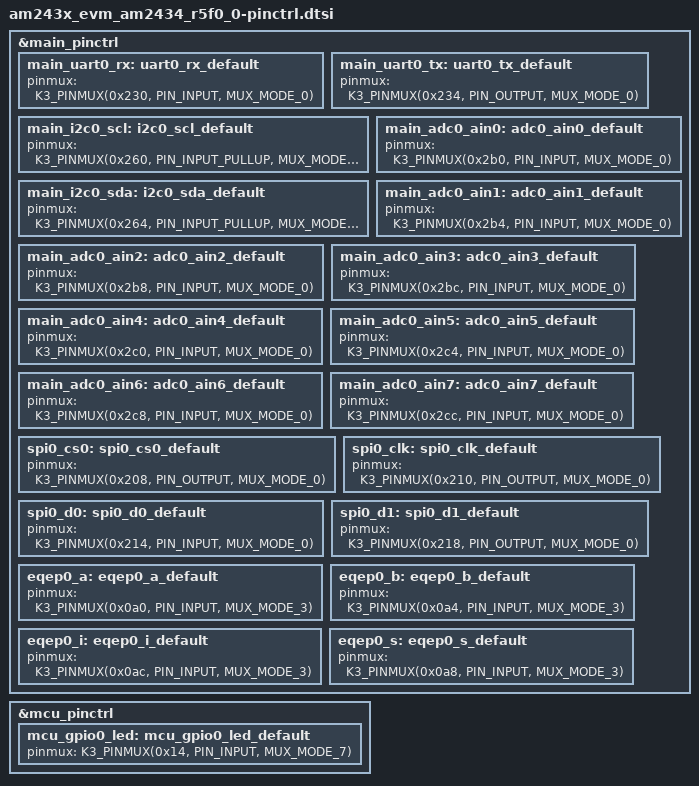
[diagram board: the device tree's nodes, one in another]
/*
 * Copyright (c) 2025 Texas Instruments Incorporated
 *
 * SPDX-License-Identifier: Apache-2.0
 */

#include <zephyr/dt-bindings/pinctrl/ti-k3-pinctrl.h>

&main_pinctrl {
	status = "okay";

	main_uart0_rx: uart0_rx_default {
		pinmux = <K3_PINMUX(0x230, PIN_INPUT, MUX_MODE_0)>;
	};

	main_uart0_tx: uart0_tx_default {
		pinmux = <K3_PINMUX(0x234, PIN_OUTPUT, MUX_MODE_0)>;
	};

	main_i2c0_scl: i2c0_scl_default {
		pinmux = <K3_PINMUX(0x260, PIN_INPUT_PULLUP, MUX_MODE_0)>;
	};

	main_i2c0_sda: i2c0_sda_default {
		pinmux = <K3_PINMUX(0x264, PIN_INPUT_PULLUP, MUX_MODE_0)>;
	};

	main_adc0_ain0: adc0_ain0_default {
		pinmux = <K3_PINMUX(0x2b0, PIN_INPUT, MUX_MODE_0)>;
	};

	main_adc0_ain1: adc0_ain1_default {
		pinmux = <K3_PINMUX(0x2b4, PIN_INPUT, MUX_MODE_0)>;
	};

	main_adc0_ain2: adc0_ain2_default {
		pinmux = <K3_PINMUX(0x2b8, PIN_INPUT, MUX_MODE_0)>;
	};

	main_adc0_ain3: adc0_ain3_default {
		pinmux = <K3_PINMUX(0x2bc, PIN_INPUT, MUX_MODE_0)>;
	};

	main_adc0_ain4: adc0_ain4_default {
		pinmux = <K3_PINMUX(0x2c0, PIN_INPUT, MUX_MODE_0)>;
	};

	main_adc0_ain5: adc0_ain5_default {
		pinmux = <K3_PINMUX(0x2c4, PIN_INPUT, MUX_MODE_0)>;
	};

	main_adc0_ain6: adc0_ain6_default {
		pinmux = <K3_PINMUX(0x2c8, PIN_INPUT, MUX_MODE_0)>;
	};

	main_adc0_ain7: adc0_ain7_default {
		pinmux = <K3_PINMUX(0x2cc, PIN_INPUT, MUX_MODE_0)>;
	};

	spi0_cs0: spi0_cs0_default {
		pinmux = <K3_PINMUX(0x208, PIN_OUTPUT, MUX_MODE_0)>;
	};

	spi0_clk: spi0_clk_default {
		pinmux = <K3_PINMUX(0x210, PIN_OUTPUT, MUX_MODE_0)>;
	};

	spi0_d0: spi0_d0_default {
		pinmux = <K3_PINMUX(0x214, PIN_INPUT, MUX_MODE_0)>;
	};

	spi0_d1: spi0_d1_default {
		pinmux = <K3_PINMUX(0x218, PIN_OUTPUT, MUX_MODE_0)>;
	};

	eqep0_a: eqep0_a_default {
		pinmux = <K3_PINMUX(0x0a0, PIN_INPUT, MUX_MODE_3)>; /* (N16) EQEP0_A */
	};

	eqep0_b: eqep0_b_default {
		pinmux = <K3_PINMUX(0x0a4, PIN_INPUT, MUX_MODE_3)>; /* (N17) EQEP0_B */
	};

	eqep0_i: eqep0_i_default {
		pinmux = <K3_PINMUX(0x0ac, PIN_INPUT, MUX_MODE_3)>; /* (R20) EQEP0_I */
	};

	eqep0_s: eqep0_s_default {
		pinmux = <K3_PINMUX(0x0a8, PIN_INPUT, MUX_MODE_3)>; /* (R19) EQEP0_S */
	};
};

&mcu_pinctrl {
	status = "okay";

	mcu_gpio0_led: mcu_gpio0_led_default {
		pinmux = <K3_PINMUX(0x14, PIN_INPUT, MUX_MODE_7)>;
	};
};
